# APM32F105xx register map
File version: 1.0
CPU: CM3 r2p1, little endian, no MPU, no FPU, 4 interrupt priority bits
Registers are 32-bit, read-write, reset 0x0 unless marked. A register's access mark holds for its fields unless they carry their own. Offsets are from the block's base; [hi:lo] are bit positions; {n}, {i} and the like mark numbered series; 'fields as' and 'values as' point back to an identical list.

## DAC — Digital to analog converter
Base 0x40007400
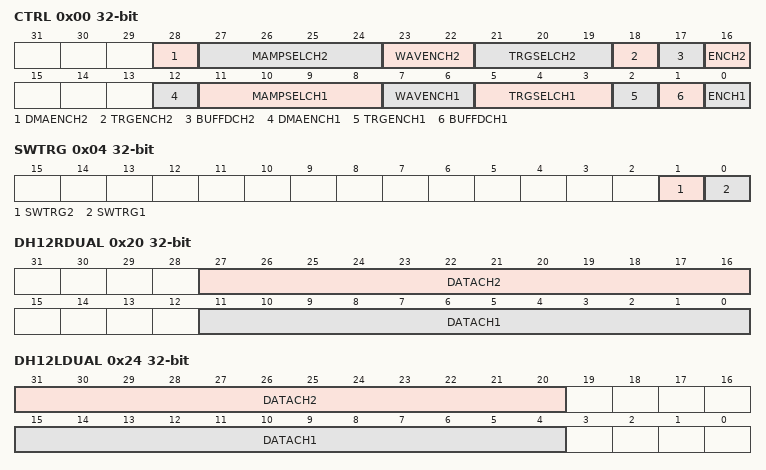
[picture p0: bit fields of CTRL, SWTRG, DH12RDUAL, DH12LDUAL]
0x00 CTRL — Control register (DAC_CTRL)
  [28] DMAENCH2 — DAC channel2 DMA enable
  [27:24] MAMPSELCH2 — DAC channel2 mask/amplitude selector
  [23:22] WAVENCH2 — DAC channel2 noise/triangle wave generation enable
  [21:19] TRGSELCH2 — DAC channel2 trigger selection
  [18] TRGENCH2 — DAC channel2 trigger enable
  [17] BUFFDCH2 — DAC channel2 output buffer disable
  [16] ENCH2 — DAC channel2 enable
  [12] DMAENCH1 — DAC channel1 DMA enable
  [11:8] MAMPSELCH1 — DAC channel1 mask/amplitude selector
  [7:6] WAVENCH1 — DAC channel1 noise/triangle wave generation enable
  [5:3] TRGSELCH1 — DAC channel1 trigger selection
  [2] TRGENCH1 — DAC channel1 trigger enable
  [1] BUFFDCH1 — DAC channel1 output buffer disable
  [0] ENCH1 — DAC channel1 enable
0x04 SWTRG wo — DAC software trigger register (DAC_SWTRG)
  [1] SWTRG2 — DAC channel2 software trigger
  [0] SWTRG1 — DAC channel1 software trigger
0x08 DH12R1 — DAC channel1 12-bit right-aligned data holding register(DAC_DH12R1)
  [11:0] DATA — DAC channel1 12-bit right-aligned data
0x0C DH12L1 — DAC channel1 12-bit left aligned data holding register (DAC_DH12L1)
  [15:4] DATA — DAC channel1 12-bit left-aligned data
0x10 DH8R1 — DAC channel1 8-bit right aligned data holding register (DAC_DH8R1)
  [7:0] DATA — DAC channel1 8-bit right-aligned data
0x14 DH12R2 — DAC channel1 12-bit right-aligned data holding register(DAC_DH12R2)
  [11:0] DATA — DAC channel2 12-bit right-aligned data
0x18 DH12L2 — DAC channel1 12-bit left aligned data holding register (DAC_DH12L2)
  [15:4] DATA — DAC channel2 12-bit left-aligned data
0x1C DH8R2 — DAC channel1 8-bit right aligned data holding register (DAC_DH8R1)
  [7:0] DATA — DAC channel2 8-bit right-aligned data
0x20 DH12RDUAL — Dual DAC 12-bit right-aligned data holding register (DAC_DH12RDUAL), Bits 31:28 Reserved, Bits 15:12 Reserved
  [27:16] DATACH2 — DAC channel2 12-bit right-aligned data
  [11:0] DATACH1 — DAC channel1 12-bit right-aligned data
0x24 DH12LDUAL — DUAL DAC 12-bit left aligned data holding register (DAC_DH12LDUAL), Bits 19:16 Reserved, Bits 3:0 Reserved
  [31:20] DATACH2 — DAC channel2 12-bit right-aligned data
  [15:4] DATACH1 — DAC channel1 12-bit left-aligned data
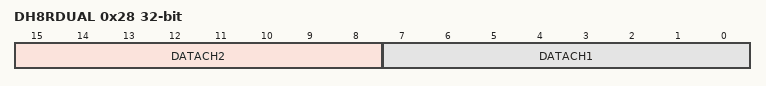
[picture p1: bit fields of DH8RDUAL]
0x28 DH8RDUAL — DUAL DAC 8-bit right aligned data holding register (DAC_DH8RDUAL), Bits 31:16 Reserved
  [15:8] DATACH2 — DAC channel2 8-bit right-aligned data
  [7:0] DATACH1 — DAC channel1 8-bit right-aligned data
0x2C DATAOCH1 ro — DAC channel1 data output register (DAC_DATAOCH1)
  [11:0] DATA — DAC channel1 data output
0x30 DATAOCH2 ro — DAC channel2 data output register (DAC_DATAOCH2)
  [11:0] DATA — DAC channel2 data output

## DBGMCU — Debug support
Base 0xE0042000
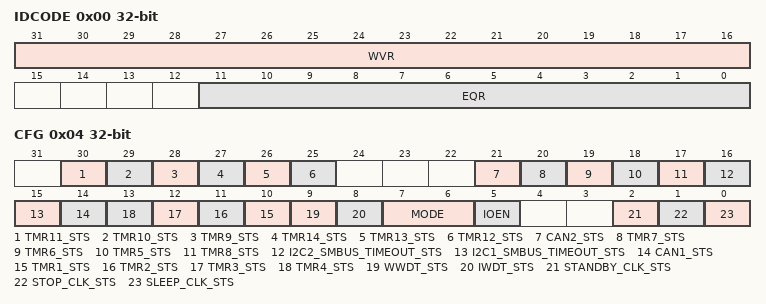
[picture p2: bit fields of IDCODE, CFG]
0x00 IDCODE ro — DBGMCU_IDCODE
  [31:16] WVR — Wafer Version Recognition
  [11:0] EQR — Equipment Recognition
0x04 CFG — DBGMCU_CFG
  [30] TMR11_STS, [29] TMR10_STS, [28] TMR9_STS, [27] TMR14_STS, [26] TMR13_STS, [25] TMR12_STS, [21] CAN2_STS, [20] TMR7_STS, [19] TMR6_STS, [18] TMR5_STS, [17] TMR8_STS, [16] I2C2_SMBUS_TIMEOUT_STS, [15] I2C1_SMBUS_TIMEOUT_STS, [14] CAN1_STS, [n+9] TMR{n}_STS (n=1..4), [9] WWDT_STS, [8] IWDT_STS, [7:6] MODE, [5] IOEN, [2] STANDBY_CLK_STS, [1] STOP_CLK_STS, [0] SLEEP_CLK_STS

## DMC — Dynamic memory controler
Base 0xA0000000
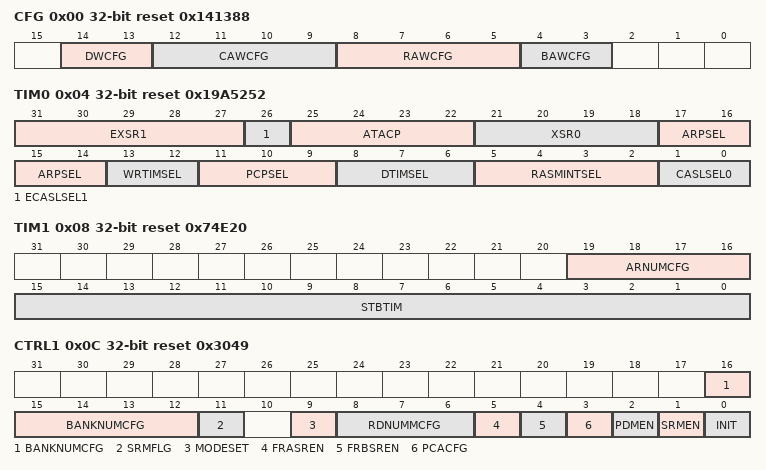
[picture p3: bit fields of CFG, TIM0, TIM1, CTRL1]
0x00 CFG reset 0x141388 — Configuraion register
  [14:13] DWCFG, [12:9] CAWCFG, [8:5] RAWCFG, [4:3] BAWCFG
0x04 TIM0 reset 0x19A5252 — Timing register 0
  [31:27] EXSR1, [26] ECASLSEL1, [25:22] ATACP, [21:18] XSR0, [17:14] ARPSEL, [13:12] WRTIMSEL, [11:9] PCPSEL, [8:6] DTIMSEL, [5:2] RASMINTSEL, [1:0] CASLSEL0
0x08 TIM1 reset 0x74E20 — Timing register 1
  [19:16] ARNUMCFG, [15:0] STBTIM
0x0C CTRL1 access per field reset 0x3049 — Control register 1
  [16:12] BANKNUMCFG rw
  [11] SRMFLG ro
  [9] MODESET rw
  [8:6] RDNUMMCFG rw — RDNUMCFG
  [5] FRASREN rw
  [4] FRBSREN rw
  [3] PCACFG rw
  [2] PDMEN rw
  [1] SRMEN rw
  [0] INIT rw
0x10 REF reset 0xC3 — refresh register
  [15:0] RCYCCFG
0x14 CHIPSEL — Chip select register
  [31:16] BACHIPSEL
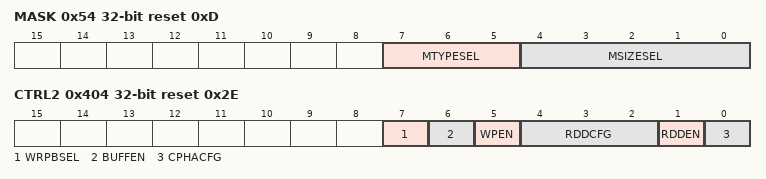
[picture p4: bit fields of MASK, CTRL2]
0x54 MASK reset 0xD
  [7:5] MTYPESEL, [4:0] MSIZESEL
0x400 SW — switch register
  [0] MCSW — Memory Controller Function Switch
0x404 CTRL2 reset 0x2E — Control register 2
  [7] WRPBSEL, [6] BUFFEN, [5] WPEN, [4:2] RDDCFG, [1] RDDEN, [0] CPHACFG

## OTG_FS_HOST — USB on the go full speed
Base 0x50000400
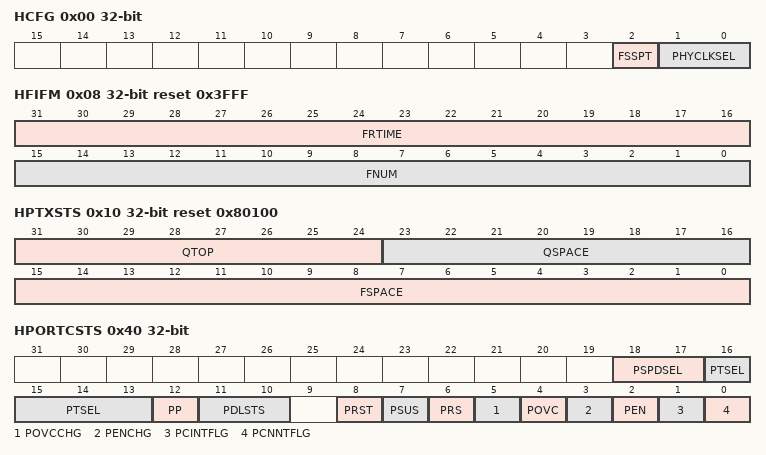
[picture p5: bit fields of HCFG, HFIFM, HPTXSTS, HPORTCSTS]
0x00 HCFG access per field — OTG_FS host configuration register (OTG_FS_HCFG)
  [2] FSSPT ro — FS- and LS-only support
  [1:0] PHYCLKSEL rw — FS/LS PHY clock select
0x04 HFIVL reset 0xEA60 — OTG_FS Host frame interval register
  [15:0] FIVL — Frame interval
0x08 HFIFM ro reset 0x3FFF — OTG_FS host frame number/frame time remaining register (OTG_FS_HFNUM)
  [31:16] FRTIME — Frame time remaining
  [15:0] FNUM — Frame number
0x10 HPTXSTS access per field reset 0x80100 — OTG_FS_Host periodic transmit FIFO/queue status register (OTG_FS_HPTXSTS)
  [31:24] QTOP ro — Top of the periodic transmit request queue
  [23:16] QSPACE ro — Periodic transmit request queue space available
  [15:0] FSPACE rw — Periodic transmit data FIFO space available
0x14 HACHINT ro — OTG_FS Host all channels interrupt register
  [15:0] ACHINT — Channel interrupts
0x18 HACHIMASK — OTG_FS host all channels interrupt mask register
  [15:0] ACHIMASK — Channel interrupt mask
0x40 HPORTCSTS access per field — OTG_FS host port control and status register (OTG_FS_HPRT)
  [18:17] PSPDSEL ro — Port speed
  [16:13] PTSEL rw — Port test control
  [12] PP rw — Port power
  [11:10] PDLSTS ro — Port line status
  [8] PRST rw — Port reset
  [7] PSUS rw — Port suspend
  [6] PRS rw — Port resume
  [5] POVCCHG rw — Port overcurrent change
  [4] POVC ro — Port overcurrent active
  [3] PENCHG rw — Port enable/disable change
  [2] PEN rw — Port enable
  [1] PCINTFLG rw — Port connect detected
  [0] PCNNTFLG ro — Port connect status
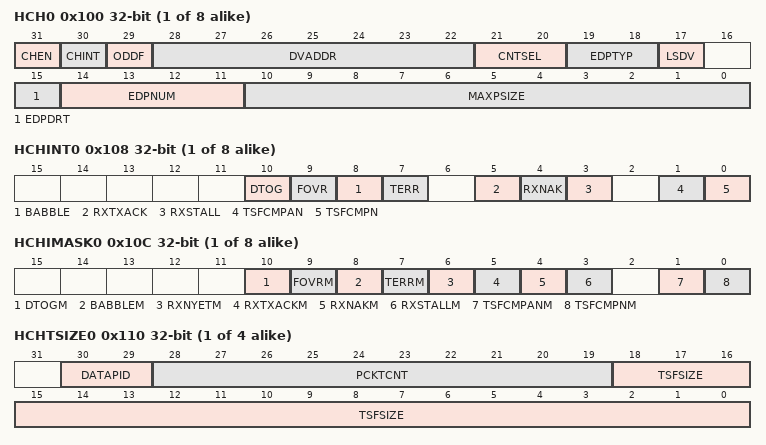
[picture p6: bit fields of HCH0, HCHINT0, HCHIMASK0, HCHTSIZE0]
{0x100+0x20*i} HCH{i} (i=0..7) — OTG_FS host channel-{i} characteristics register (OTG_FS_HCCHAR{i})
  [31] CHEN — Channel enable
  [30] CHINT — Channel disable
  [29] ODDF — Odd frame
  [28:22] DVADDR — Device address
  [21:20] CNTSEL — Multicount
  [19:18] EDPTYP — Endpoint type
  [17] LSDV — Low-speed device
  [15] EDPDRT — Endpoint direction
  [14:11] EDPNUM — Endpoint number
  [10:0] MAXPSIZE — Maximum packet size
{0x108+0x20*i} HCHINT{i} (i=0..7) — OTG_FS host channel-{i} interrupt register (OTG_FS_HCINT{i})
  [10] DTOG — Data toggle error
  [9] FOVR — Frame overrun
  [8] BABBLE — Babble error
  [7] TERR — Transaction error
  [5] RXTXACK — ACK response received/transmitted interrupt
  [4] RXNAK — NAK response received interrupt
  [3] RXSTALL — STALL response received interrupt
  [1] TSFCMPAN — Channel halted
  [0] TSFCMPN — Transfer completed
{0x10C+0x20*i} HCHIMASK{i} (i=0..7) — OTG_FS host channel-{i} mask register (OTG_FS_HCINTMSK{i})
  [10] DTOGM — Data toggle error mask
  [9] FOVRM — Frame overrun mask
  [8] BABBLEM — Babble error mask
  [7] TERRM — Transaction error mask
  [6] RXNYETM — response received interrupt mask
  [5] RXTXACKM — ACK response received/transmitted interrupt mask
  [4] RXNAKM — NAK response received interrupt mask
  [3] RXSTALLM — STALL response received interrupt mask
  [1] TSFCMPANM — Channel halted mask
  [0] TSFCMPNM — Transfer completed mask
{0x110+0x20*i} HCHTSIZE{i} (i=0..3) — OTG_FS host channel-{i} transfer size register
  [30:29] DATAPID
  [28:19] PCKTCNT — Packet count
  [18:0] TSFSIZE — Transfer size
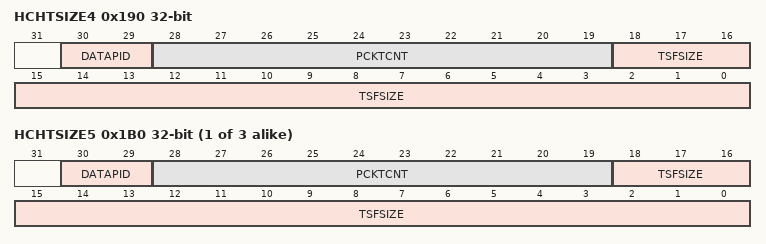
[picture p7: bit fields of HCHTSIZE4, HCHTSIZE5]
0x190 HCHTSIZE4 — OTG_FS host channel-x transfer size register
  fields as HCHTSIZE0
{0x110+0x20*i} HCHTSIZE{i} (i=5..7) — OTG_FS host channel-{i} transfer size register
  fields as HCHTSIZE0

## OTG_FS_PWRCLK — USB on the go full speed
Base 0x50000E00
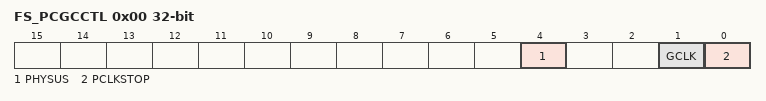
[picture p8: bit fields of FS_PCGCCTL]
0x00 FS_PCGCCTL — OTG_FS power and clock gating control register
  [4] PHYSUS — PHY Suspended
  [1] GCLK — Gate HCLK
  [0] PCLKSTOP — Stop PHY clock
